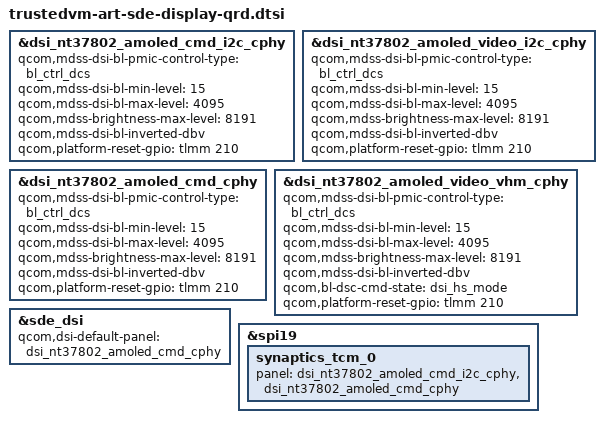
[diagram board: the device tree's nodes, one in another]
// SPDX-License-Identifier: BSD-3-Clause
/*
 * Copyright (c) Qualcomm Technologies, Inc. and/or its subsidiaries.
 */

#include "trustedvm-art-sde-display.dtsi"

&dsi_nt37802_amoled_cmd_i2c_cphy {
	qcom,mdss-dsi-bl-pmic-control-type = "bl_ctrl_dcs";
	qcom,mdss-dsi-bl-min-level = <15>;
	qcom,mdss-dsi-bl-max-level = <4095>;
	qcom,mdss-brightness-max-level = <8191>;
	qcom,mdss-dsi-bl-inverted-dbv;
	qcom,platform-reset-gpio = <&tlmm 210 0>;
};

&dsi_nt37802_amoled_video_i2c_cphy {
	qcom,mdss-dsi-bl-pmic-control-type = "bl_ctrl_dcs";
	qcom,mdss-dsi-bl-min-level = <15>;
	qcom,mdss-dsi-bl-max-level = <4095>;
	qcom,mdss-brightness-max-level = <8191>;
	qcom,mdss-dsi-bl-inverted-dbv;
	qcom,platform-reset-gpio = <&tlmm 210 0>;
};

&dsi_nt37802_amoled_cmd_cphy {
	qcom,mdss-dsi-bl-pmic-control-type = "bl_ctrl_dcs";
	qcom,mdss-dsi-bl-min-level = <15>;
	qcom,mdss-dsi-bl-max-level = <4095>;
	qcom,mdss-brightness-max-level = <8191>;
	qcom,mdss-dsi-bl-inverted-dbv;
	qcom,platform-reset-gpio = <&tlmm 210 0>;
};

&dsi_nt37802_amoled_video_vhm_cphy {
	qcom,mdss-dsi-bl-pmic-control-type = "bl_ctrl_dcs";
	qcom,mdss-dsi-bl-min-level = <15>;
	qcom,mdss-dsi-bl-max-level = <4095>;
	qcom,mdss-brightness-max-level = <8191>;
	qcom,mdss-dsi-bl-inverted-dbv;
	qcom,bl-dsc-cmd-state = "dsi_hs_mode";
	qcom,platform-reset-gpio = <&tlmm 210 0>;
};

&sde_dsi {
	qcom,dsi-default-panel = <&dsi_nt37802_amoled_cmd_cphy>;
};

&spi19 {
	synaptics_tcm_0 {
		panel = <&dsi_nt37802_amoled_cmd_i2c_cphy
			&dsi_nt37802_amoled_cmd_cphy>;
	};
};
